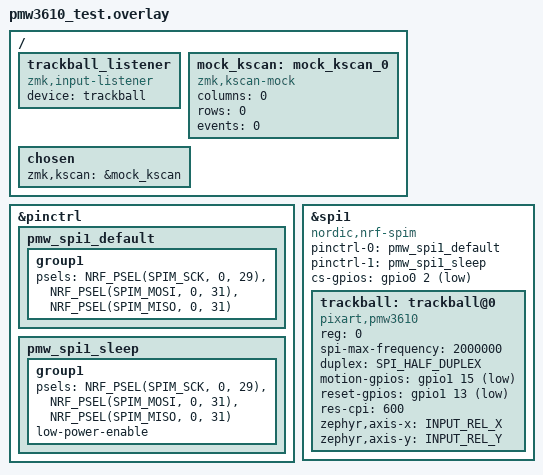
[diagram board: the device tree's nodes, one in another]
#include <zephyr/dt-bindings/input/input-event-codes.h>
#include <zephyr/dt-bindings/spi/spi.h>

  &pinctrl {
      pmw_spi1_default: pmw_spi1_default {
          group1 {
              psels = <NRF_PSEL(SPIM_SCK, 0, 29)>,
                      <NRF_PSEL(SPIM_MOSI, 0, 31)>,
                      <NRF_PSEL(SPIM_MISO, 0, 31)>;
          };
      };

      pmw_spi1_sleep: pmw_spi1_sleep {
          group1 {
              psels = <NRF_PSEL(SPIM_SCK, 0, 29)>,
                      <NRF_PSEL(SPIM_MOSI, 0, 31)>,
                      <NRF_PSEL(SPIM_MISO, 0, 31)>;
              low-power-enable;
          };
      };
  };

  &spi1 {
      status = "okay";
      compatible = "nordic,nrf-spim";

      pinctrl-0 = <&pmw_spi1_default>;
      pinctrl-1 = <&pmw_spi1_sleep>;
      pinctrl-names = "default", "sleep";

      cs-gpios = <&gpio0 2 GPIO_ACTIVE_LOW>;

      trackball: trackball@0 {
          status = "okay";
          compatible = "pixart,pmw3610";
          reg = <0>;
          spi-max-frequency = <2000000>;
          duplex = <SPI_HALF_DUPLEX>;

          motion-gpios = <&gpio1 15 (GPIO_ACTIVE_LOW | GPIO_PULL_UP)>;
          reset-gpios = <&gpio1 13 GPIO_ACTIVE_LOW>;

          res-cpi = <600>;
          zephyr,axis-x = <INPUT_REL_X>;
          zephyr,axis-y = <INPUT_REL_Y>;
      };
  };
  
  / {
      trackball_listener {
          compatible = "zmk,input-listener";
          device = <&trackball>;
      };

      // No keys are attached, so use a zero-key scanner.
      mock_kscan: mock_kscan_0 {
          compatible = "zmk,kscan-mock";
          columns = <0>;
          rows = <0>;
          events = <0>;
      };

      chosen {
          zmk,kscan = &mock_kscan;
      };
  };
